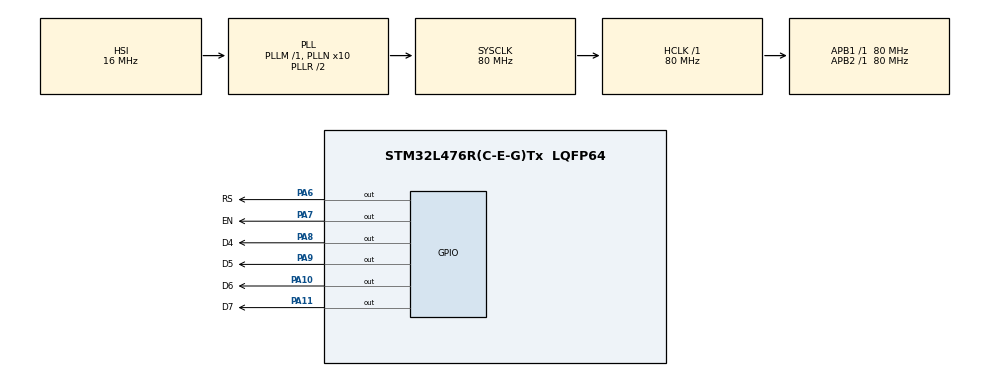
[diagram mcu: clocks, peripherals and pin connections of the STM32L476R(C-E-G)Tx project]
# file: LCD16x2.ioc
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Mcu.Family=STM32L4
Mcu.Name=STM32L476R(C-E-G)Tx
Mcu.Package=LQFP64
NVIC.PriorityGroup=NVIC_PRIORITYGROUP_4
PA10.GPIO_Label=D6
PA10.GPIO_PuPd=GPIO_PULLDOWN
PA10.Signal=GPIO_Output
PA11.GPIO_Label=D7
PA11.GPIO_PuPd=GPIO_PULLDOWN
PA11.Signal=GPIO_Output
PA6.GPIO_Label=RS
PA6.GPIO_PuPd=GPIO_PULLDOWN
PA6.Signal=GPIO_Output
PA7.GPIO_Label=EN
PA7.GPIO_PuPd=GPIO_PULLDOWN
PA7.Signal=GPIO_Output
PA8.GPIO_Label=D4
PA8.GPIO_PuPd=GPIO_PULLDOWN
PA8.Signal=GPIO_Output
PA9.GPIO_Label=D5
PA9.GPIO_PuPd=GPIO_PULLDOWN
PA9.Signal=GPIO_Output
PH0-OSC_IN\ (PH0).Mode=HSE-External-Oscillator
PH0-OSC_IN\ (PH0).Signal=RCC_OSC_IN
PH1-OSC_OUT\ (PH1).Mode=HSE-External-Oscillator
PH1-OSC_OUT\ (PH1).Signal=RCC_OSC_OUT
ProjectManager.HeapSize=0x200
ProjectManager.StackSize=0x400
ProjectManager.TargetToolchain=STM32CubeIDE
RCC.ADCFreq_Value=64000000
RCC.AHBFreq_Value=80000000
RCC.APB1Freq_Value=80000000
RCC.APB1TimFreq_Value=80000000
RCC.APB2Freq_Value=80000000
RCC.APB2TimFreq_Value=80000000
RCC.CortexFreq_Value=80000000
RCC.HCLKFreq_Value=80000000
RCC.HSE_VALUE=8000000
RCC.HSI_VALUE=16000000
RCC.LSE_VALUE=32768
RCC.MSI_VALUE=4000000
RCC.PLLN=10
RCC.PLLSourceVirtual=RCC_PLLSOURCE_HSI
RCC.SYSCLKFreq_VALUE=80000000
RCC.SYSCLKSource=RCC_SYSCLKSOURCE_PLLCLK
RCC.USBFreq_Value=64000000
RCC.VCOOutputFreq_Value=160000000
board=custom

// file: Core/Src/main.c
/* USER CODE BEGIN Header */
/**
  ******************************************************************************
  * @file           : main.c
  * @brief          : Main program body
  ******************************************************************************
  * @attention
  *
  * Copyright (c) 2024 STMicroelectronics.
  * All rights reserved.
  *
  * This software is licensed under terms that can be found in the LICENSE file
  * in the root directory of this software component.
  * If no LICENSE file comes with this software, it is provided AS-IS.
  *
  ******************************************************************************
  */
/* USER CODE END Header */
#include "main.h"

/* USER CODE BEGIN Includes */
#include "LCDdriver.h"
/* USER CODE END Includes */

void SystemClock_Config(void);
static void MX_GPIO_Init(void);

int main(void)
{

  /* MCU Configuration--------------------------------------------------------*/

  /* Reset of all peripherals, Initializes the Flash interface and the Systick. */
  HAL_Init();

  /* Configure the system clock */
  SystemClock_Config();

  /* Initialize all configured peripherals */
  MX_GPIO_Init();
  /* USER CODE BEGIN 2 */
LCD_init();
LCD_clear();
LCD_char('L');
  /* USER CODE END 2 */

  /* Infinite loop */
  /* USER CODE BEGIN WHILE */
  while (1)
  {
	  LCD_clear();
	  LCD_char('L');
    /* USER CODE END WHILE */

  }
}

void SystemClock_Config(void)
{
  RCC_OscInitTypeDef RCC_OscInitStruct = {0};
  RCC_ClkInitTypeDef RCC_ClkInitStruct = {0};

  /** Configure the main internal regulator output voltage
  */
  if (HAL_PWREx_ControlVoltageScaling(PWR_REGULATOR_VOLTAGE_SCALE1) != HAL_OK)
  {
    Error_Handler();
  }

  /** Initializes the RCC Oscillators according to the specified parameters
  * in the RCC_OscInitTypeDef structure.
  */
  RCC_OscInitStruct.OscillatorType = RCC_OSCILLATORTYPE_HSI;
  RCC_OscInitStruct.HSIState = RCC_HSI_ON;
  RCC_OscInitStruct.HSICalibrationValue = RCC_HSICALIBRATION_DEFAULT;
  RCC_OscInitStruct.PLL.PLLState = RCC_PLL_ON;
  RCC_OscInitStruct.PLL.PLLSource = RCC_PLLSOURCE_HSI;
  RCC_OscInitStruct.PLL.PLLM = 1;
  RCC_OscInitStruct.PLL.PLLN = 10;
  RCC_OscInitStruct.PLL.PLLP = RCC_PLLP_DIV7;
  RCC_OscInitStruct.PLL.PLLQ = RCC_PLLQ_DIV2;
  RCC_OscInitStruct.PLL.PLLR = RCC_PLLR_DIV2;
  if (HAL_RCC_OscConfig(&RCC_OscInitStruct) != HAL_OK)
  {
    Error_Handler();
  }

  /** Initializes the CPU, AHB and APB buses clocks
  */
  RCC_ClkInitStruct.ClockType = RCC_CLOCKTYPE_HCLK|RCC_CLOCKTYPE_SYSCLK
                              |RCC_CLOCKTYPE_PCLK1|RCC_CLOCKTYPE_PCLK2;
  RCC_ClkInitStruct.SYSCLKSource = RCC_SYSCLKSOURCE_PLLCLK;
  RCC_ClkInitStruct.AHBCLKDivider = RCC_SYSCLK_DIV1;
  RCC_ClkInitStruct.APB1CLKDivider = RCC_HCLK_DIV1;
  RCC_ClkInitStruct.APB2CLKDivider = RCC_HCLK_DIV1;

  if (HAL_RCC_ClockConfig(&RCC_ClkInitStruct, FLASH_LATENCY_4) != HAL_OK)
  {
    Error_Handler();
  }
}

static void MX_GPIO_Init(void)
{
  GPIO_InitTypeDef GPIO_InitStruct = {0};

  /* GPIO Ports Clock Enable */
  __HAL_RCC_GPIOH_CLK_ENABLE();
  __HAL_RCC_GPIOA_CLK_ENABLE();

  /*Configure GPIO pin Output Level */
  HAL_GPIO_WritePin(GPIOA, RS_Pin|EN_Pin|D4_Pin|D5_Pin
                          |D6_Pin|D7_Pin, GPIO_PIN_RESET);

  /*Configure GPIO pins : RS_Pin EN_Pin D4_Pin D5_Pin
                           D6_Pin D7_Pin */
  GPIO_InitStruct.Pin = RS_Pin|EN_Pin|D4_Pin|D5_Pin
                          |D6_Pin|D7_Pin;
  GPIO_InitStruct.Mode = GPIO_MODE_OUTPUT_PP;
  GPIO_InitStruct.Pull = GPIO_PULLDOWN;
  GPIO_InitStruct.Speed = GPIO_SPEED_FREQ_LOW;
  HAL_GPIO_Init(GPIOA, &GPIO_InitStruct);

}

void Error_Handler(void)
{
  __disable_irq();
  while (1)
  {
  }
}
